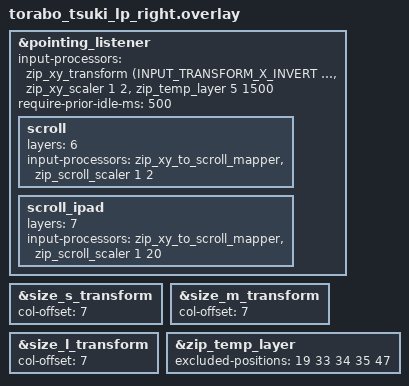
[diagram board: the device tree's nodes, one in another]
#define TORABO_TSUKI_LP_RIGHT 1
#define TORABO_TSUKI_LP_MATRIX_COL_OFFSET 7

#include "torabo_tsuki_lp.dtsi"
#include <input/processors.dtsi>
#include <dt-bindings/zmk/input_transform.h>

&pointing_listener {
    input-processors = 
        <&zip_xy_transform (INPUT_TRANSFORM_X_INVERT | INPUT_TRANSFORM_Y_INVERT)>,
        <&zip_xy_scaler 1 2>,
        <&zip_temp_layer 5 1500>;

        require-prior-idle-ms = <500>;

    /* Pキー長押し（Layer 6）：PC用スクロール（1/2減速） */
    scroll {
        layers = <6>;
        input-processors = 
        <&zip_xy_to_scroll_mapper>,
        <&zip_scroll_scaler 1 2>;
    };

    /* Oキー長押し（Layer 7）：iPad用スクロール（1/12超減速） */
    scroll_ipad {
        layers = <7>;
        input-processors = 
        <&zip_xy_to_scroll_mapper>,
        <&zip_scroll_scaler 1 20>;
    };
};

&size_s_transform { col-offset = <7>; };
&size_m_transform { col-offset = <7>; };
&size_l_transform { col-offset = <7>; };

/* オートマウス起動中でもレイヤーが自動解除されないキー位置（クリックキー等） */
&zip_temp_layer {
    excluded-positions = <19 33 34 35 47>;
};
